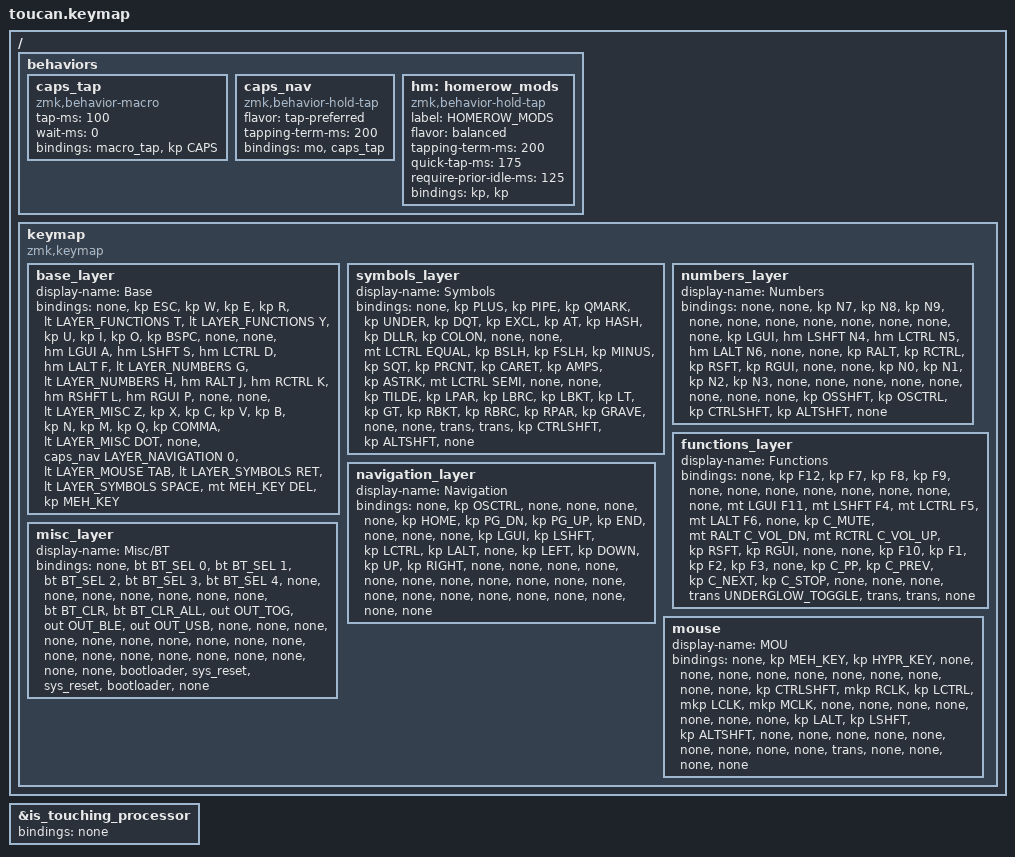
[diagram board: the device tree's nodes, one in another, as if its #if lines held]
/*
 * Copyright (c) 2020 The ZMK Contributors
 *
 * SPDX-License-Identifier: MIT
 */

#include <behaviors.dtsi>
#include <dt-bindings/zmk/keys.h>
#include <dt-bindings/zmk/bt.h>
#include <dt-bindings/zmk/outputs.h>
#include <dt-bindings/zmk/rgb.h>
#include <dt-bindings/zmk/pointing.h>

// Toucan2 has a status LED, not an RGB underglow strip.
#if IS_ENABLED(CONFIG_ZMK_RGB_UNDERGLOW)
#define UNDERGLOW_TOGGLE &rgb_ug RGB_TOG
#else
#define UNDERGLOW_TOGGLE &none
#endif

// Layer definitions
#define LAYER_BASE        0
#define LAYER_SYMBOLS     1
#define LAYER_NUMBERS     2
#define LAYER_FUNCTIONS   3
#define LAYER_NAVIGATION  4
#define LAYER_MISC        5
#define LAYER_MOUSE       6

// Modifier combination aliases
#define MEH_KEY  LC(LS(LALT))
#define HYPR_KEY LC(LS(LA(LGUI)))
#define CTRLSHFT LC(LSHIFT)
#define OSSHFT   LG(LSHIFT)
#define ALTSHFT  LA(LSHIFT)
#define OSCTRL   LG(LCTRL)

/ {
    behaviors {
        // Give macOS enough key-down time to recognize the Caps Lock tap.
        caps_tap: caps_tap {
            compatible = "zmk,behavior-macro";
            #binding-cells = <0>;
            tap-ms = <100>;
            wait-ms = <0>;
            bindings = <&macro_tap &kp CAPS>;
        };

        caps_nav: caps_nav {
            compatible = "zmk,behavior-hold-tap";
            #binding-cells = <2>;
            flavor = "tap-preferred";
            tapping-term-ms = <200>;
            bindings = <&mo>, <&caps_tap>;
        };

        hm: homerow_mods {
            compatible = "zmk,behavior-hold-tap";
            label = "HOMEROW_MODS";
            #binding-cells = <2>;
            flavor = "balanced";
            tapping-term-ms = <200>;
            quick-tap-ms = <175>;
            require-prior-idle-ms = <125>;
            bindings = <&kp>, <&kp>;
        };
    };

    keymap {
        compatible = "zmk,keymap";

        base_layer {
            display-name = "Base";
// ---------------------------------------------------------------------------------------------------------------------------------
// |      |  ESC       |  W         |  E         |  R         |  T (LT3)   |   |  Y (LT3)   |  U         |  I         |  O         |  BSPC      |      |
// |      |  A (GUI)   |  S (SFT)   |  D (CTL)   |  F (ALT)   |  G (LT2)   |   |  H (LT2)   |  J (ALT)   |  K (CTL)   |  L (SFT)   |  P (GUI)   |      |
// |      |  Z (LT5)   |  X         |  C         |  V         |  B         |   |  N         |  M         |  Q         |  ,         |  . (LT5)   |      |
//                                  | CAPS (LT4) | TAB (LT6)  | ENT (LT1)  |   | SPC (LT1)  | DEL (MEH)  | MEH        |
            bindings = <
   &none  &kp ESC     &kp W        &kp E        &kp R        &lt LAYER_FUNCTIONS T       &lt LAYER_FUNCTIONS Y  &kp U        &kp I        &kp O        &kp BSPC           &none
   &none  &hm LGUI A  &hm LSHFT S  &hm LCTRL D  &hm LALT F   &lt LAYER_NUMBERS G         &lt LAYER_NUMBERS H    &hm RALT J   &hm RCTRL K  &hm RSHFT L  &hm RGUI P         &none
   &none  &lt LAYER_MISC Z &kp X   &kp C        &kp V        &kp B                       &kp N                  &kp M        &kp Q        &kp COMMA    &lt LAYER_MISC DOT &none
                                   &caps_nav LAYER_NAVIGATION 0 &lt LAYER_MOUSE TAB &lt LAYER_SYMBOLS RET  &lt LAYER_SYMBOLS SPACE &mt MEH_KEY DEL &kp MEH_KEY
            >;
        };

        symbols_layer {
            display-name = "Symbols";
// ---------------------------------------------------------------------------------------------------------------------------------
// |      |  +         |  |         |  ?         |  _         |  "         |   |  !         |  @         |  #         |  $         |  :         |      |
// |      |  = (CTL)   |  \         |  /         |  -         |  '         |   |  %         |  ^         |  &         |  *         |  ; (CTL)   |      |
// |      |  ~         |  (         |  {         |  [         |  <         |   |  >         |  ]         |  }         |  )         |  `         |      |
//                                  |            |  TRANS     |  TRANS     |   | CTRL+SHFT  | ALT+SHFT   |            |
            bindings = <
   &none  &kp PLUS          &kp PIPE  &kp QMARK &kp UNDER &kp DQT           &kp EXCL        &kp AT    &kp HASH  &kp DLLR   &kp COLON        &none
   &none  &mt LCTRL EQUAL   &kp BSLH  &kp FSLH  &kp MINUS &kp SQT           &kp PRCNT       &kp CARET &kp AMPS  &kp ASTRK  &mt LCTRL SEMI   &none
   &none  &kp TILDE         &kp LPAR  &kp LBRC  &kp LBKT  &kp LT            &kp GT          &kp RBKT  &kp RBRC  &kp RPAR   &kp GRAVE        &none
                                      &none     &trans    &trans            &kp CTRLSHFT    &kp ALTSHFT &none
            >;
        };

        numbers_layer {
            display-name = "Numbers";
// ---------------------------------------------------------------------------------------------------------------------------------
// |      |            |  7         |  8         |  9         |            |   |            |            |            |            |            |      |
// |      |  GUI       |  4 (SFT)   |  5 (CTL)   |  6 (ALT)   |            |   |            |  RALT      |  RCTL      |  RSFT      |  RGUI      |      |
// |      |  0         |  1         |  2         |  3         |            |   |            |            |            |            |            |      |
//                                  |            |  GUI+SHFT  |  GUI+CTL   |   | CTRL+SHFT  | ALT+SHFT   |            |
            bindings = <
   &none  &none       &kp N7       &kp N8       &kp N9       &none          &none         &none        &none        &none        &none        &none
   &none  &kp LGUI    &hm LSHFT N4 &hm LCTRL N5 &hm LALT N6  &none          &none         &kp RALT     &kp RCTRL    &kp RSFT     &kp RGUI     &none
   &none  &kp N0      &kp N1       &kp N2       &kp N3       &none          &none         &none        &none        &none        &none        &none
                                   &none        &kp OSSHFT   &kp OSCTRL     &kp CTRLSHFT  &kp ALTSHFT  &none
            >;
        };

        functions_layer {
            display-name = "Functions";
// ---------------------------------------------------------------------------------------------------------------------------------
// |      |  F12       |  F7        |  F8        |  F9        |            |   |            |            |            |            |            |      |
// |      |  F11 (GUI) |  F4 (SFT)  |  F5 (CTL)  |  F6 (ALT)  |            |   |  MUTE      |  VOL- (ALT)|  VOL+ (CTL)|  RSFT      |  RGUI      |      |
// |      |  F10       |  F1        |  F2        |  F3        |            |   |  PLAY/PAUSE|  PREV      |  NEXT      |  STOP      |            |      |
//                                  |            |  TRANS     |  RGB_TOG   |   |  TRANS     |  TRANS     |            |
            bindings = <
   &none  &kp F12          &kp F7        &kp F8        &kp F9       &none           &none       &none             &none              &none        &none        &none
   &none  &mt LGUI F11     &mt LSHFT F4  &mt LCTRL F5  &mt LALT F6  &none           &kp C_MUTE  &mt RALT C_VOL_DN &mt RCTRL C_VOL_UP &kp RSFT     &kp RGUI     &none
   &none  &kp F10          &kp F1        &kp F2        &kp F3       &none           &kp C_PP    &kp C_PREV        &kp C_NEXT         &kp C_STOP   &none        &none
                                         &none         &trans       UNDERGLOW_TOGGLE &trans      &trans            &none
            >;
        };

        navigation_layer {
            display-name = "Navigation";
// ---------------------------------------------------------------------------------------------------------------------------------
// |      |  GUI+CTL   |            |            |            |            |   |  HOME      |  PG_DN     |  PG_UP     |  END       |            |      |
// |      |  LGUI      |  LSHFT     |  LCTRL     |  LALT      |            |   |  LEFT      |  DOWN      |  UP        |  RIGHT     |            |      |
// |      |            |            |            |            |            |   |            |            |            |            |            |      |
//                                  |            |            |            |   |            |            |            |
            bindings = <
   &none  &kp OSCTRL  &none       &none       &none       &none             &kp HOME    &kp PG_DN   &kp PG_UP   &kp END     &none        &none
   &none  &kp LGUI    &kp LSHFT   &kp LCTRL   &kp LALT    &none             &kp LEFT    &kp DOWN    &kp UP      &kp RIGHT   &none        &none
   &none  &none       &none       &none       &none       &none             &none       &none       &none       &none       &none        &none
                                  &none       &none       &none             &none       &none       &none
            >;
        };

        misc_layer {
            display-name = "Misc/BT";
// ---------------------------------------------------------------------------------------------------------------------------------
// |      |  BT_SEL 0  |  BT_SEL 1  |  BT_SEL 2  |  BT_SEL 3  |  BT_SEL 4  |   |            |            |            |            |            |      |
// |      |  BT_CLR    |  BT_CLR_ALL|  OUT_TOG   |  OUT_BLE   |  OUT_USB   |   |            |            |            |            |            |      |
// |      |            |            |            |            |            |   |            |            |            |            |            |      |
//                                  |            |  BOOTLDR   |  SYS_RST   |   |  SYS_RST   |  BOOTLDR   |            |
            bindings = <
   &none  &bt BT_SEL 0  &bt BT_SEL 1    &bt BT_SEL 2  &bt BT_SEL 3 &bt BT_SEL 4    &none        &none        &none       &none       &none        &none
   &none  &bt BT_CLR    &bt BT_CLR_ALL  &out OUT_TOG  &out OUT_BLE &out OUT_USB    &none        &none        &none       &none       &none        &none
   &none  &none         &none           &none         &none        &none           &none        &none        &none       &none       &none        &none
                                        &none         &bootloader  &sys_reset      &sys_reset   &bootloader  &none
            >;
        };

        // Hold the Tab thumb key for Dilemma-style mouse buttons and modifiers.
        mouse {
            display-name = "MOU";
            bindings = <
                &none &kp MEH_KEY  &kp HYPR_KEY &none        &none     &none       &none &none &none &none &none &none
                &none &kp CTRLSHFT &mkp RCLK    &kp LCTRL    &mkp LCLK &mkp MCLK   &none &none &none &none &none &none
                &none &kp LALT     &kp LSHFT    &kp ALTSHFT  &none     &none       &none &none &none &none &none &none
                                                   &none &trans &none            &none &none &none
            >;
        };

    };
};

// Mouse is activated manually; touching the trackpad must not change layers.
&is_touching_processor {
    bindings = <&none>;
};
